AUTOSAR XML (schema 4-2-1)
# Copyright (c) 2018 Vector Informatik GmbH.
# License is restricted to the usage with CBD1800257 (D01) for MSR_Vector_SLP4.
# Please contact Vector Informatik whenever you need further information concerning the license conditions.
standard types defined: boolean, sint8, uint16, uint8
package /VehicleProject
  system System
package /NM
  nm config NmConfig: can-nm-cluster-coupling=coupled-cluster=CAN00_CAN
    can nm cluster CAN00_CAN: communication-cluster=CAN00, nm-channel-id=0, nm-msg-cycle-time=0.1, nm-network-timeout=1, nm-repeat-message-time=0.4, nm-user-data-length=6, nm-wait-bus-sleep-time=0.75
      can nm node MyECU: controller=CT_CAN00, nm-if-ecu=MyECU_CAN, nm-node-id=0, rx-nm-pdu=msg_nm_RearECU_oCAN00, tx-nm-pdu=msg_nm_MyECU_oCAN00, nm-msg-cycle-offset=0, nm-msg-reduced-time=0.05, nm-range-config={lower-can-id=1024, upper-can-id=1087}
      can nm node RearECU: nm-if-ecu=RearECU_CAN, nm-node-id=1, rx-nm-pdu=msg_nm_MyECU_oCAN00, tx-nm-pdu=msg_nm_RearECU_oCAN00, nm-msg-cycle-offset=0, nm-msg-reduced-time=0.05, nm-range-config={lower-can-id=1024, upper-can-id=1087}
      can nm node Tester: nm-if-ecu=Tester_CAN, nm-node-id=0, nm-passive-mode-enabled=true, nm-msg-cycle-offset=0, nm-msg-reduced-time=0.05, nm-range-config={lower-can-id=1024, upper-can-id=1087}
    nm-if-ecus:
      nm ecu MyECU_CAN: ecu-instance=MyECU, nm-node-id-enabled=true, nm-user-data-enabled=true
      nm ecu RearECU_CAN: nm-node-id-enabled=true, nm-user-data-enabled=true
      nm ecu Tester_CAN: nm-node-id-enabled=true, nm-passive-mode-enabled=true, nm-user-data-enabled=true
package /TP
  can tp config CAN00_CAN: communication-cluster=CAN00, can-tp-ecu{cycle-time-main-function=0.005, ecu-instance=MyECU}
    can tp channel TPCH: channel-id=0, channel-mode=FULL-DUPLEX-MODE
    can-tp-connection addressing-format=STANDARD, can-tp-channel=TPCH, data-pdu=msg_diag_RequestGlobal_Tp_oCAN00, receiver=TN_MyECU, ta-type=FUNCTIONAL, tp-sdu=msg_diag_RequestGlobal_oCAN00, transmitter=TN_Tester:
      ident msg_diag_RequestGlobal_oTN_Tester
    can-tp-connection addressing-format=STANDARD, can-tp-channel=TPCH, data-pdu=msg_diag_Request_MyECU_Tp_oCAN00, flow-control-pdu=msg_diag_Response_MyECU_Tp_oCAN00, receiver=TN_MyECU, ta-type=PHYSICAL, tp-sdu=msg_diag_Request_MyECU_oCAN00, transmitter=TN_Tester:
      ident msg_diag_Request_MyECU_oTN_MyECU
    can-tp-connection addressing-format=STANDARD, can-tp-channel=TPCH, data-pdu=msg_diag_Response_MyECU_Tp_oCAN00, flow-control-pdu=msg_diag_Request_MyECU_Tp_oCAN00, receiver=TN_Tester, ta-type=PHYSICAL, tp-sdu=msg_diag_Response_MyECU_oCAN00, transmitter=TN_MyECU:
      ident msg_diag_Response_MyECU_oTN_MyECU
    can tp node TN_MyECU: connector=CN_CAN00
    can tp node TN_Tester
package /Cluster
  can cluster CAN00: protocol-name=CAN
    can physical channel CHNL: comm-connectors=CN_CAN00
      frame msg_diag_Request_MyECU_oCAN00: id 0x610, to MyECU, frame-length=8, can-addressing-mode=STANDARD
        n pdu msg_diag_Request_MyECU_Tp_oCAN00: length=8
      frame msg_diag_RequestGlobal_oCAN00: id 0x614, to MyECU, frame-length=8, can-addressing-mode=STANDARD
        n pdu msg_diag_RequestGlobal_Tp_oCAN00: length=8
      frame msg_diag_Response_MyECU_oCAN00: id 0x612, from MyECU, frame-length=8, can-addressing-mode=STANDARD
        n pdu msg_diag_Response_MyECU_Tp_oCAN00: length=8
      frame msg_MyECU_Lamp_oCAN00: id 0x511, from MyECU, frame-length=8, can-addressing-mode=STANDARD
        pdu msg_MyECU_Lamp_oCAN00: length=8, minimum-delay=0, transmission-mode-false-timing=cyclic-timing={time-offset=0, time-period=0.1}, transmission-mode-true-timing=cyclic-timing={time-offset=0, time-period=0.1}, unused-bit-pattern=0
          signal sig_LampCnt_omsg_MyECU_Lamp_oCAN00: start 7, 8 bit, big-endian, init-value=0, base-type=uint8, range raw 0..255, transfer-property=PENDING
      frame msg_nm_MyECU_oCAN00: id 0x400, from MyECU, frame-length=8, can-addressing-mode=STANDARD
        nm pdu msg_nm_MyECU_oCAN00: length=8, unused-bit-pattern=0
      frame msg_nm_RearECU_oCAN00: id 0x401, to MyECU, frame-length=8, can-addressing-mode=STANDARD
        nm pdu msg_nm_RearECU_oCAN00: length=8, unused-bit-pattern=0
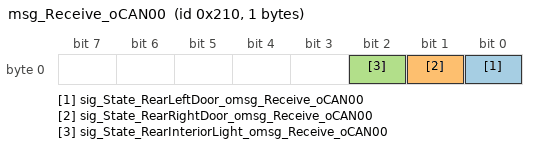
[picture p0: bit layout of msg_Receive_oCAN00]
      frame msg_Receive_oCAN00: id 0x210, to MyECU, frame-length=1, can-addressing-mode=STANDARD
        pdu msg_Receive_oCAN00: length=1, minimum-delay=0, transmission-mode-false-timing=cyclic-timing={time-offset=0, time-period=0.1}, transmission-mode-true-timing=cyclic-timing={time-offset=0, time-period=0.1}, unused-bit-pattern=0
          signal sig_State_RearLeftDoor_omsg_Receive_oCAN00: start 0, 1 bit, little-endian, init-value=0, base-type=boolean, range raw 0..1, transfer-property=PENDING, to MyECU
          signal sig_State_RearRightDoor_omsg_Receive_oCAN00: start 1, 1 bit, little-endian, init-value=0, base-type=boolean, range raw 0..1, transfer-property=PENDING, to MyECU
          signal sig_State_RearInteriorLight_omsg_Receive_oCAN00: start 2, 1 bit, little-endian, init-value=0, base-type=boolean, range raw 0..1, transfer-property=PENDING, to MyECU
      frame msg_Transmit_oCAN00: id 0x200, from MyECU, frame-length=1, can-addressing-mode=STANDARD
        pdu msg_Transmit_oCAN00: length=1, minimum-delay=0, transmission-mode-false-timing=cyclic-timing={time-offset=0, time-period=0.1}, transmission-mode-true-timing=cyclic-timing={time-offset=0, time-period=0.1}, unused-bit-pattern=0
          signal sig_RearInteriorLight_omsg_Transmit_oCAN00: start 0, 1 bit, little-endian, init-value=0, base-type=boolean, range raw 0..1, transfer-property=PENDING
      frame VCU_Ingition_oCAN00: id 0x222, from MyECU, frame-length=8, can-addressing-mode=STANDARD
        pdu VCU_Ingition_oCAN00: length=8, minimum-delay=0, unused-bit-pattern=0
          signal VCU_Ingition_Mode_oVCU_Ingition_oCAN00: start 0, 2 bit, little-endian, init-value=0, base-type=sint8, range raw -2..1, transfer-property=PENDING
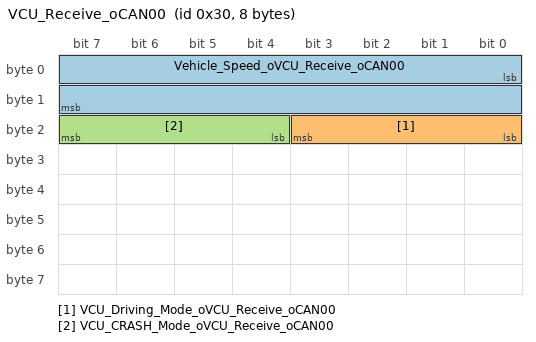
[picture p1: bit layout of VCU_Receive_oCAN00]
      frame VCU_Receive_oCAN00: id 0x30, to MyECU, frame-length=8, can-addressing-mode=STANDARD
        pdu VCU_Receive_oCAN00: length=8, minimum-delay=0, unused-bit-pattern=0
          signal Vehicle_Speed_oVCU_Receive_oCAN00: start 0, 16 bit, little-endian, init-value=0, base-type=uint16, compu {phys=raw*0.1 for raw 0..2550; unit km/h}, unit=km/h, transfer-property=PENDING, to MyECU
          signal VCU_Driving_Mode_oVCU_Receive_oCAN00: start 16, 4 bit, little-endian, init-value=0, base-type=uint8, compu {0=Cx0_Normal_Mode (Normal Mode), 1=Cx1_Sport_Mode (Sport Mode), 2=Cx2_Eco_Mode (Eco Mode)}, range raw 0..15, transfer-property=PENDING, to MyECU
          signal VCU_CRASH_Mode_oVCU_Receive_oCAN00: start 20, 4 bit, little-endian, init-value=0, base-type=uint8, range raw 0..15, transfer-property=PENDING, to MyECU
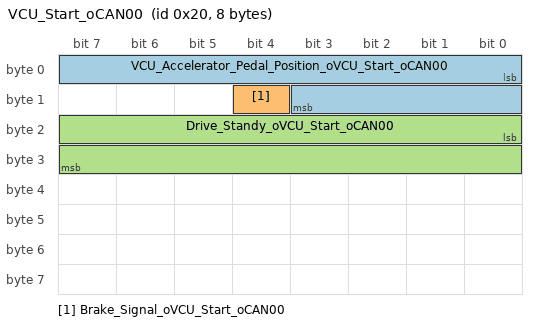
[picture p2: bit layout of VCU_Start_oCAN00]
      frame VCU_Start_oCAN00: id 0x20, from MyECU, frame-length=8, can-addressing-mode=STANDARD
        pdu VCU_Start_oCAN00: length=8, minimum-delay=0, unused-bit-pattern=0
          signal VCU_Accelerator_Pedal_Position_oVCU_Start_oCAN00: start 0, 12 bit, little-endian, init-value=0, base-type=uint16, range raw 0..100, unit=%, transfer-property=PENDING
          signal Brake_Signal_oVCU_Start_oCAN00: start 12, 1 bit, little-endian, init-value=0, base-type=boolean, compu {0=Cx0_Brake_Released (Brake Released), 1=Cx1_Brake_Applied (Brake Applied)}, transfer-property=PENDING
          signal Drive_Standy_oVCU_Start_oCAN00: start 16, 16 bit, little-endian, init-value=0, base-type=uint16, compu {phys=raw*0.1 for raw 0..2550; unit km/h}, unit=km/h, transfer-property=PENDING
      pdu triggering PT_msg_diag_Request_MyECU: pdu=msg_diag_Request_MyECU_oCAN00, to MyECU
      pdu triggering PT_msg_diag_RequestGlobal: pdu=msg_diag_RequestGlobal_oCAN00, to MyECU
      pdu triggering PT_msg_diag_Response_MyECU: pdu=msg_diag_Response_MyECU_oCAN00, from MyECU
package /ECU
  ecu instance MyECU: associated-com-i-pdu-group=[MyECU_oCAN00_Rx, MyECU_oCAN00_Tx]
    can communication controller CT_CAN00
    can communication connector CN_CAN00: comm-controller=CT_CAN00
package /IPDUGroup
  i signal i pdu group MyECU_oCAN00_Rx: communication-direction=IN, i-signal-i-pdus=[msg_Receive_oCAN00, VCU_Receive_oCAN00]
  i signal i pdu group MyECU_oCAN00_Tx: communication-direction=OUT, i-signal-i-pdus=[msg_MyECU_Lamp_oCAN00, msg_Transmit_oCAN00, VCU_Ingition_oCAN00, VCU_Start_oCAN00]
package /PDU
  dcm i pdu msg_diag_Request_MyECU_oCAN00: length=8, diag-pdu-type=DIAG-REQUEST
  dcm i pdu msg_diag_RequestGlobal_oCAN00: length=7, diag-pdu-type=DIAG-REQUEST
  dcm i pdu msg_diag_Response_MyECU_oCAN00: length=8, diag-pdu-type=DIAG-RESPONSE
package /DataType/Unit
  unit U_kmYh: display-name=km/h
  unit U_p: display-name=%
